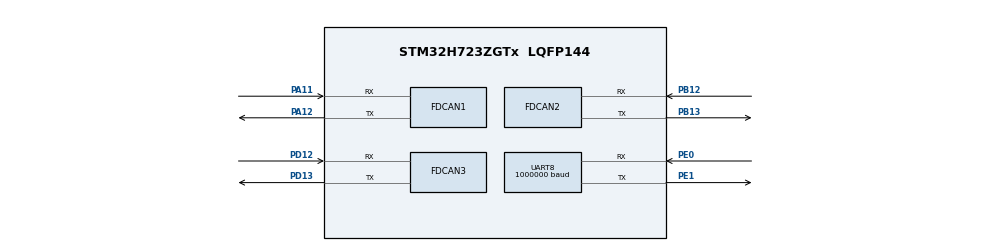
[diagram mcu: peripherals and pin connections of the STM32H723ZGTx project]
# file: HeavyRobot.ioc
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CORTEX_M7.default_mode_Activation=1
CRC.CRCLength=CRC_POLYLENGTH_16B
CRC.DefaultInitValueUse=DEFAULT_INIT_VALUE_DISABLE
CRC.DefaultPolynomialUse=DEFAULT_POLYNOMIAL_DISABLE
CRC.GeneratingPolynomial=X12+X5+X0
CRC.InitValue=0
CRC.InputDataInversionMode=CRC_INPUTDATA_INVERSION_BYTE
CRC.OutputDataInversionMode=CRC_OUTPUTDATA_INVERSION_ENABLE
Dma.Request0=UART8_RX
Dma.Request1=UART8_TX
Dma.UART8_RX.0.Direction=DMA_PERIPH_TO_MEMORY
Dma.UART8_RX.0.EventEnable=DISABLE
Dma.UART8_RX.0.FIFOMode=DMA_FIFOMODE_DISABLE
Dma.UART8_RX.0.Instance=DMA1_Stream0
Dma.UART8_RX.0.MemDataAlignment=DMA_MDATAALIGN_BYTE
Dma.UART8_RX.0.MemInc=DMA_MINC_ENABLE
Dma.UART8_RX.0.Mode=DMA_NORMAL
Dma.UART8_RX.0.PeriphDataAlignment=DMA_PDATAALIGN_BYTE
Dma.UART8_RX.0.PeriphInc=DMA_PINC_DISABLE
Dma.UART8_RX.0.Polarity=HAL_DMAMUX_REQ_GEN_RISING
Dma.UART8_RX.0.Priority=DMA_PRIORITY_LOW
Dma.UART8_RX.0.RequestNumber=1
Dma.UART8_RX.0.SignalID=NONE
Dma.UART8_RX.0.SyncEnable=DISABLE
Dma.UART8_RX.0.SyncPolarity=HAL_DMAMUX_SYNC_NO_EVENT
Dma.UART8_RX.0.SyncRequestNumber=1
Dma.UART8_RX.0.SyncSignalID=NONE
Dma.UART8_TX.1.Direction=DMA_MEMORY_TO_PERIPH
Dma.UART8_TX.1.EventEnable=DISABLE
Dma.UART8_TX.1.FIFOMode=DMA_FIFOMODE_DISABLE
Dma.UART8_TX.1.Instance=DMA1_Stream1
Dma.UART8_TX.1.MemDataAlignment=DMA_MDATAALIGN_BYTE
Dma.UART8_TX.1.MemInc=DMA_MINC_ENABLE
Dma.UART8_TX.1.Mode=DMA_NORMAL
Dma.UART8_TX.1.PeriphDataAlignment=DMA_PDATAALIGN_BYTE
Dma.UART8_TX.1.PeriphInc=DMA_PINC_DISABLE
Dma.UART8_TX.1.Polarity=HAL_DMAMUX_REQ_GEN_RISING
Dma.UART8_TX.1.Priority=DMA_PRIORITY_LOW
Dma.UART8_TX.1.RequestNumber=1
Dma.UART8_TX.1.SignalID=NONE
Dma.UART8_TX.1.SyncEnable=DISABLE
Dma.UART8_TX.1.SyncPolarity=HAL_DMAMUX_SYNC_NO_EVENT
Dma.UART8_TX.1.SyncRequestNumber=1
Dma.UART8_TX.1.SyncSignalID=NONE
FDCAN1.CalculateBaudRateNominal=960000
FDCAN1.CalculateTimeBitNominal=1041
FDCAN1.CalculateTimeQuantumNominal=104.16666666666666
FDCAN1.DataPrescaler=2
FDCAN1.DataSyncJumpWidth=15
FDCAN1.DataTimeSeg1=32
FDCAN1.DataTimeSeg2=15
FDCAN1.NominalPrescaler=10
FDCAN1.NominalSyncJumpWidth=15
FDCAN1.NominalTimeSeg1=7
FDCAN1.NominalTimeSeg2=2
FDCAN1.RxFifo0ElmtsNbr=4
FDCAN1.StdFiltersNbr=1
FDCAN1.TxFifoQueueElmtsNbr=3
FDCAN2.CalculateBaudRateNominal=1000000
FDCAN2.CalculateTimeBitNominal=1000
FDCAN2.CalculateTimeQuantumNominal=125.0
FDCAN2.DataPrescaler=2
FDCAN2.DataSyncJumpWidth=15
FDCAN2.DataTimeSeg1=32
FDCAN2.DataTimeSeg2=15
FDCAN2.FrameFormat=FDCAN_FRAME_CLASSIC
FDCAN2.MessageRAMOffset=512
FDCAN2.NominalPrescaler=12
FDCAN2.NominalSyncJumpWidth=15
FDCAN2.NominalTimeSeg1=5
FDCAN2.NominalTimeSeg2=2
FDCAN2.RxFifo0ElmtsNbr=4
FDCAN2.StdFiltersNbr=1
FDCAN2.TxFifoQueueElmtsNbr=8
FDCAN3.CalculateBaudRateNominal=960000
FDCAN3.CalculateTimeBitNominal=1041
FDCAN3.CalculateTimeQuantumNominal=104.16666666666666
FDCAN3.DataPrescaler=2
FDCAN3.DataSyncJumpWidth=15
FDCAN3.DataTimeSeg1=32
FDCAN3.DataTimeSeg2=15
FDCAN3.MessageRAMOffset=1024
FDCAN3.NominalPrescaler=10
FDCAN3.NominalSyncJumpWidth=15
FDCAN3.NominalTimeSeg1=7
FDCAN3.NominalTimeSeg2=2
FDCAN3.RxFifo0ElmtsNbr=4
FDCAN3.StdFiltersNbr=1
FDCAN3.TxFifoQueueElmtsNbr=3
FREERTOS.BinarySemaphores01=StartSem,Static,StartSemControlBlock,Depleted
FREERTOS.Tasks01=SafetyTask,48,512,StartSafetyTask,As weak,NULL,Static,SafetyTaskBuffer,SafetyTaskControlBlock;MotorTask,47,512,StartMotorTask,As weak,NULL,Static,MotorTaskBuffer,MotorTaskControlBlock;BodyTask,8,512,StartBodyTask,As weak,NULL,Static,RobotTaskBuffer,RobotTaskControlBlock
FREERTOS.configCHECK_FOR_STACK_OVERFLOW=2
FREERTOS.configTOTAL_HEAP_SIZE=50000
FREERTOS.configUSE_IDLE_HOOK=1
FREERTOS.configUSE_MALLOC_FAILED_HOOK=1
FREERTOS.configUSE_TICK_HOOK=1
Mcu.Family=STM32H7
Mcu.Name=STM32H723ZGTx
Mcu.Package=LQFP144
NVIC.DMA1_Stream0_IRQn=true\:5\:0\:false\:false\:true\:true\:true\:true\:true
NVIC.DMA1_Stream1_IRQn=true\:5\:0\:false\:false\:true\:true\:true\:true\:true
NVIC.FDCAN1_IT0_IRQn=true\:5\:0\:true\:false\:true\:true\:true\:true\:true
NVIC.FDCAN1_IT1_IRQn=true\:6\:0\:true\:false\:true\:true\:true\:true\:true
NVIC.FDCAN2_IT0_IRQn=true\:5\:0\:true\:false\:true\:true\:true\:true\:true
NVIC.FDCAN2_IT1_IRQn=true\:6\:0\:true\:false\:true\:true\:true\:true\:true
NVIC.FDCAN3_IT0_IRQn=true\:5\:0\:true\:false\:true\:true\:true\:true\:true
NVIC.FDCAN3_IT1_IRQn=true\:6\:0\:true\:false\:true\:true\:true\:true\:true
NVIC.PriorityGroup=NVIC_PRIORITYGROUP_4
NVIC.TIM17_IRQn=true\:15\:0\:false\:false\:true\:false\:false\:true\:true
NVIC.TIM1_UP_IRQn=true\:7\:0\:true\:false\:true\:true\:true\:true\:true
NVIC.TIM6_DAC_IRQn=true\:5\:0\:false\:false\:true\:true\:true\:true\:true
NVIC.TIM8_UP_TIM13_IRQn=true\:6\:0\:true\:false\:true\:true\:true\:true\:true
NVIC.TimeBase=TIM17_IRQn
NVIC.TimeBaseIP=TIM17
NVIC.UART8_IRQn=true\:5\:0\:false\:false\:true\:true\:true\:true\:true
PA11.Mode=FDCAN_Activate
PA11.Signal=FDCAN1_RX
PA12.Mode=FDCAN_Activate
PA12.Signal=FDCAN1_TX
PA13(JTMS/SWDIO).Mode=Serial_Wire
PA13(JTMS/SWDIO).Signal=DEBUG_JTMS-SWDIO
PA14(JTCK/SWCLK).Mode=Serial_Wire
PA14(JTCK/SWCLK).Signal=DEBUG_JTCK-SWCLK
PB12.Mode=FDCAN_Activate
PB12.Signal=FDCAN2_RX
PB13.Mode=FDCAN_Activate
PB13.Signal=FDCAN2_TX
PD12.Mode=FDCAN_Activate
PD12.Signal=FDCAN3_RX
PD13.Mode=FDCAN_Activate
PD13.Signal=FDCAN3_TX
PE0.Mode=Asynchronous
PE0.Signal=UART8_RX
PE1.Mode=Asynchronous
PE1.Signal=UART8_TX
PH0-OSC_IN.Mode=HSE-External-Oscillator
PH0-OSC_IN.Signal=RCC_OSC_IN
PH1-OSC_OUT.Mode=HSE-External-Oscillator
PH1-OSC_OUT.Signal=RCC_OSC_OUT
ProjectManager.HeapSize=0x400
ProjectManager.StackSize=0x200
ProjectManager.TargetToolchain=MDK-ARM V5.32
RCC.ADCFreq_Value=93750000
RCC.APB1Freq_Value=120000000
RCC.APB2Freq_Value=120000000
RCC.APB3Freq_Value=120000000
RCC.APB4Freq_Value=120000000
RCC.CortexFreq_Value=480000000
RCC.D1PPRE=RCC_APB3_DIV2
RCC.D2PPRE1=RCC_APB1_DIV2
RCC.D2PPRE2=RCC_APB2_DIV2
RCC.D3PPRE=RCC_APB4_DIV2
RCC.DIVM1=5
RCC.DIVM2=2
RCC.DIVN1=96
RCC.DIVN2=15
RCC.DIVN3=4
RCC.DIVP1=1
RCC.DIVQ1=5
RCC.HCLKFreq_Value=240000000
RCC.HPRE=RCC_HCLK_DIV2
RCC.HSE_VALUE=25000000
RCC.PLL2FRACN=0
RCC.PLL3FRACN=0
RCC.PLLFRACN=0
RCC.PLLSourceVirtual=RCC_PLLSOURCE_HSE
RCC.SYSCLKFreq_VALUE=480000000
RCC.SYSCLKSource=RCC_SYSCLKSOURCE_PLLCLK
RCC.SupplySource=PWR_LDO_SUPPLY
RCC.USBFreq_Value=96000000
TIM6.Period=1000-1
TIM6.Prescaler=240-1
UART8.BaudRate=1000000
VP_CRC_VS_CRC.Mode=CRC_Activate
VP_FREERTOS_VS_CMSIS_V2.Mode=CMSIS_V2
VP_MEMORYMAP_VS_MEMORYMAP.Mode=CurAppReg
VP_SYS_VS_tim17.Mode=TIM17
VP_TIM1_VS_ClockSourceINT.Mode=Internal
VP_TIM23_VS_ClockSourceINT.Mode=Internal
VP_TIM2_VS_ClockSourceINT.Mode=Internal
VP_TIM6_VS_ClockSourceINT.Mode=Enable_Timer
VP_TIM8_VS_ClockSourceINT.Mode=Internal
board=custom

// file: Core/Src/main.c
/* USER CODE BEGIN Header */
/**
  ******************************************************************************
  * @file           : main.c
  * @brief          : Main program body
  ******************************************************************************
  * @attention
  *
  * Copyright (c) 2026 STMicroelectronics.
  * All rights reserved.
  *
  * This software is licensed under terms that can be found in the LICENSE file
  * in the root directory of this software component.
  * If no LICENSE file comes with this software, it is provided AS-IS.
  *
  ******************************************************************************
  */
/* USER CODE END Header */
#include "main.h"
#include "FreeRTOS.h"
#include "cmsis_os2.h"
#include "crc.h"
#include "dma.h"
#include "fdcan.h"
#include "tim.h"
#include "usart.h"
#include "gpio.h"

/* USER CODE BEGIN Includes */
#include "arm_app.h"
#include <stdio.h>
/* USER CODE END Includes */

void SystemClock_Config(void);
static void MPU_Config(void);
void MX_FREERTOS_Init(void);

int main(void)
{

  /* MPU Configuration--------------------------------------------------------*/
  MPU_Config();

  /* MCU Configuration--------------------------------------------------------*/

  /* Reset of all peripherals, Initializes the Flash interface and the Systick. */
  HAL_Init();

  /* Configure the system clock */
  SystemClock_Config();

  /* Initialize all configured peripherals */
  MX_GPIO_Init();
  MX_DMA_Init();
  MX_FDCAN1_Init();
  MX_FDCAN2_Init();
  MX_FDCAN3_Init();
  MX_TIM1_Init();
  MX_TIM8_Init();
  MX_TIM2_Init();
  MX_CRC_Init();
  MX_TIM6_Init();
  MX_TIM23_Init();
  MX_UART8_Init();
  /* USER CODE BEGIN 2 */

///* 关节角 -> 位姿 */
//float q_seed[6] = {0.3f, -0.7f, 1.1f, 0.2f, 0.0f, -0.4f};
//ArmPos_t pose;
//Matrix4x4 T_target;
//Arm_ForwardKinematics(q_seed, &pose, &T_target);   /* T_out 不需要就传 NULL */

//ArmIK_Model ik;
//ArmIK_Init(&ik, arm_params);             /* arm_params 在 arm_kinematics.c */
//ArmIK_SetTool(&ik, 0.0f, 0.0f, 0.0f);

//ArmPos_t target = {
//    .x = 0.25f, .y = 0.0f, .z = 0.35f,
//    .roll = 0.0f, .pitch = 1.5708f, .yaw = 0.0f,
//};

////float q_seed[6] = {0.3f, -0.7f, 1.1f, 0.2f, 0.5f, -0.4f};
////float q_min[6]  = {NULL};//{ /* 或者传 NULL */ };
////float q_max[6]  = {NULL};//{ /* 或者传 NULL */ };
//float q_out[6];

//if (ArmIK_SolvePose(&ik, &pose, q_seed, NULL, NULL, q_out)) {
//    float err = ArmIK_Residual(T_target.data, q_out);
//}

  /* USER CODE END 2 */

  /* Init scheduler */
  osKernelInitialize();  /* Call init function for freertos objects (in cmsis_os2.c) */
  MX_FREERTOS_Init();

  /* Start scheduler */
  osKernelStart();

  /* We should never get here as control is now taken by the scheduler */

  /* Infinite loop */
  while (1)
  {

  }
}

void SystemClock_Config(void)
{
  RCC_OscInitTypeDef RCC_OscInitStruct = {0};
  RCC_ClkInitTypeDef RCC_ClkInitStruct = {0};

  /** Supply configuration update enable
  */
  HAL_PWREx_ConfigSupply(PWR_LDO_SUPPLY);

  /** Configure the main internal regulator output voltage
  */
  __HAL_PWR_VOLTAGESCALING_CONFIG(PWR_REGULATOR_VOLTAGE_SCALE0);

  while(!__HAL_PWR_GET_FLAG(PWR_FLAG_VOSRDY)) {}

  /** Initializes the RCC Oscillators according to the specified parameters
  * in the RCC_OscInitTypeDef structure.
  */
  RCC_OscInitStruct.OscillatorType = RCC_OSCILLATORTYPE_HSE;
  RCC_OscInitStruct.HSEState = RCC_HSE_ON;
  RCC_OscInitStruct.PLL.PLLState = RCC_PLL_ON;
  RCC_OscInitStruct.PLL.PLLSource = RCC_PLLSOURCE_HSE;
  RCC_OscInitStruct.PLL.PLLM = 5;
  RCC_OscInitStruct.PLL.PLLN = 96;
  RCC_OscInitStruct.PLL.PLLP = 1;
  RCC_OscInitStruct.PLL.PLLQ = 5;
  RCC_OscInitStruct.PLL.PLLR = 2;
  RCC_OscInitStruct.PLL.PLLRGE = RCC_PLL1VCIRANGE_2;
  RCC_OscInitStruct.PLL.PLLVCOSEL = RCC_PLL1VCOWIDE;
  RCC_OscInitStruct.PLL.PLLFRACN = 0;
  if (HAL_RCC_OscConfig(&RCC_OscInitStruct) != HAL_OK)
  {
    Error_Handler();
  }

  /** Initializes the CPU, AHB and APB buses clocks
  */
  RCC_ClkInitStruct.ClockType = RCC_CLOCKTYPE_HCLK|RCC_CLOCKTYPE_SYSCLK
                              |RCC_CLOCKTYPE_PCLK1|RCC_CLOCKTYPE_PCLK2
                              |RCC_CLOCKTYPE_D3PCLK1|RCC_CLOCKTYPE_D1PCLK1;
  RCC_ClkInitStruct.SYSCLKSource = RCC_SYSCLKSOURCE_PLLCLK;
  RCC_ClkInitStruct.SYSCLKDivider = RCC_SYSCLK_DIV1;
  RCC_ClkInitStruct.AHBCLKDivider = RCC_HCLK_DIV2;
  RCC_ClkInitStruct.APB3CLKDivider = RCC_APB3_DIV2;
  RCC_ClkInitStruct.APB1CLKDivider = RCC_APB1_DIV2;
  RCC_ClkInitStruct.APB2CLKDivider = RCC_APB2_DIV2;
  RCC_ClkInitStruct.APB4CLKDivider = RCC_APB4_DIV2;

  if (HAL_RCC_ClockConfig(&RCC_ClkInitStruct, FLASH_LATENCY_3) != HAL_OK)
  {
    Error_Handler();
  }
}

 /* MPU Configuration */

void MPU_Config(void)
{
  MPU_Region_InitTypeDef MPU_InitStruct = {0};

  /* Disables the MPU */
  HAL_MPU_Disable();

  /** Initializes and configures the Region and the memory to be protected
  */
  MPU_InitStruct.Enable = MPU_REGION_ENABLE;
  MPU_InitStruct.Number = MPU_REGION_NUMBER0;
  MPU_InitStruct.BaseAddress = 0x0;
  MPU_InitStruct.Size = MPU_REGION_SIZE_4GB;
  MPU_InitStruct.SubRegionDisable = 0x87;
  MPU_InitStruct.TypeExtField = MPU_TEX_LEVEL0;
  MPU_InitStruct.AccessPermission = MPU_REGION_NO_ACCESS;
  MPU_InitStruct.DisableExec = MPU_INSTRUCTION_ACCESS_DISABLE;
  MPU_InitStruct.IsShareable = MPU_ACCESS_SHAREABLE;
  MPU_InitStruct.IsCacheable = MPU_ACCESS_NOT_CACHEABLE;
  MPU_InitStruct.IsBufferable = MPU_ACCESS_NOT_BUFFERABLE;

  HAL_MPU_ConfigRegion(&MPU_InitStruct);
  /* Enables the MPU */
  HAL_MPU_Enable(MPU_PRIVILEGED_DEFAULT);

}

void HAL_TIM_PeriodElapsedCallback(TIM_HandleTypeDef *htim)
{
  if (htim->Instance == TIM17)
  {
    HAL_IncTick();
  }
}

void Error_Handler(void)
{
  __disable_irq();
  while (1)
  {
  }
}

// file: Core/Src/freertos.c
/* USER CODE BEGIN Header */
/**
  ******************************************************************************
  * File Name          : freertos.c
  * Description        : Code for freertos applications
  ******************************************************************************
  * @attention
  *
  * Copyright (c) 2026 STMicroelectronics.
  * All rights reserved.
  *
  * This software is licensed under terms that can be found in the LICENSE file
  * in the root directory of this software component.
  * If no LICENSE file comes with this software, it is provided AS-IS.
  *
  ******************************************************************************
  */
/* USER CODE END Header */

#include "FreeRTOS.h"
#include "task.h"
#include "main.h"
#include "FreeRTOS.h"
#include "cmsis_os2.h"

typedef StaticTask_t osStaticThreadDef_t;
typedef StaticSemaphore_t osStaticSemaphoreDef_t;

/* Definitions for SafetyTask */
osThreadId_t SafetyTaskHandle;
uint32_t SafetyTaskBuffer[ 512 ];
osStaticThreadDef_t SafetyTaskControlBlock;
const osThreadAttr_t SafetyTask_attributes = {
  .name = "SafetyTask",
  .cb_mem = &SafetyTaskControlBlock,
  .cb_size = sizeof(SafetyTaskControlBlock),
  .stack_mem = &SafetyTaskBuffer[0],
  .stack_size = sizeof(SafetyTaskBuffer),
  .priority = (osPriority_t) osPriorityRealtime,
};
/* Definitions for MotorTask */
osThreadId_t MotorTaskHandle;
uint32_t MotorTaskBuffer[ 512 ];
osStaticThreadDef_t MotorTaskControlBlock;
const osThreadAttr_t MotorTask_attributes = {
  .name = "MotorTask",
  .cb_mem = &MotorTaskControlBlock,
  .cb_size = sizeof(MotorTaskControlBlock),
  .stack_mem = &MotorTaskBuffer[0],
  .stack_size = sizeof(MotorTaskBuffer),
  .priority = (osPriority_t) osPriorityHigh7,
};
/* Definitions for BodyTask */
osThreadId_t BodyTaskHandle;
uint32_t RobotTaskBuffer[ 512 ];
osStaticThreadDef_t RobotTaskControlBlock;
const osThreadAttr_t BodyTask_attributes = {
  .name = "BodyTask",
  .cb_mem = &RobotTaskControlBlock,
  .cb_size = sizeof(RobotTaskControlBlock),
  .stack_mem = &RobotTaskBuffer[0],
  .stack_size = sizeof(RobotTaskBuffer),
  .priority = (osPriority_t) osPriorityLow,
};
/* Definitions for StartSem */
osSemaphoreId_t StartSemHandle;
osStaticSemaphoreDef_t StartSemControlBlock;
const osSemaphoreAttr_t StartSem_attributes = {
  .name = "StartSem",
  .cb_mem = &StartSemControlBlock,
  .cb_size = sizeof(StartSemControlBlock),
};

void StartSafetyTask(void *argument);
void StartMotorTask(void *argument);
void StartBodyTask(void *argument);

void MX_FREERTOS_Init(void); /* (MISRA C 2004 rule 8.1) */

/* Hook prototypes */
void vApplicationIdleHook(void);
void vApplicationTickHook(void);
void vApplicationStackOverflowHook(xTaskHandle xTask, char *pcTaskName);
void vApplicationMallocFailedHook(void);

/* USER CODE BEGIN 2 */
void vApplicationIdleHook( void )
{
   /* vApplicationIdleHook() will only be called if configUSE_IDLE_HOOK is set
   to 1 in FreeRTOSConfig.h. It will be called on each iteration of the idle
   task. It is essential that code added to this hook function never attempts
   to block in any way (for example, call xQueueReceive() with a block time
   specified, or call vTaskDelay()). If the application makes use of the
   vTaskDelete() API function (as this demo application does) then it is also
   important that vApplicationIdleHook() is permitted to return to its calling
   function, because it is the responsibility of the idle task to clean up
   memory allocated by the kernel to any task that has since been deleted. */
}
/* USER CODE END 2 */

/* USER CODE BEGIN 3 */
void vApplicationTickHook( void )
{
   /* This function will be called by each tick interrupt if
   configUSE_TICK_HOOK is set to 1 in FreeRTOSConfig.h. User code can be
   added here, but the tick hook is called from an interrupt context, so
   code must not attempt to block, and only the interrupt safe FreeRTOS API
   functions can be used (those that end in FromISR()). */
}
/* USER CODE END 3 */

/* USER CODE BEGIN 4 */
void vApplicationStackOverflowHook(xTaskHandle xTask,char *pcTaskName)
{
   /* Run time stack overflow checking is performed if
   configCHECK_FOR_STACK_OVERFLOW is defined to 1 or 2. This hook function is
   called if a stack overflow is detected. */
}
/* USER CODE END 4 */

/* USER CODE BEGIN 5 */
void vApplicationMallocFailedHook(void)
{
   /* vApplicationMallocFailedHook() will only be called if
   configUSE_MALLOC_FAILED_HOOK is set to 1 in FreeRTOSConfig.h. It is a hook
   function that will get called if a call to pvPortMalloc() fails.
   pvPortMalloc() is called internally by the kernel whenever a task, queue,
   timer or semaphore is created. It is also called by various parts of the
   demo application. If heap_1.c or heap_2.c are used, then the size of the
   heap available to pvPortMalloc() is defined by configTOTAL_HEAP_SIZE in
   FreeRTOSConfig.h, and the xPortGetFreeHeapSize() API function can be used
   to query the size of free heap space that remains (although it does not
   provide information on how the remaining heap might be fragmented). */
}
/* USER CODE END 5 */

void MX_FREERTOS_Init(void) {

  /* Create the semaphores(s) */
  /* creation of StartSem */
  StartSemHandle = osSemaphoreNew(1, 0, &StartSem_attributes);

  /* Create the thread(s) */
  /* creation of SafetyTask */
  SafetyTaskHandle = osThreadNew(StartSafetyTask, NULL, &SafetyTask_attributes);

  /* creation of MotorTask */
  MotorTaskHandle = osThreadNew(StartMotorTask, NULL, &MotorTask_attributes);

  /* creation of BodyTask */
  BodyTaskHandle = osThreadNew(StartBodyTask, NULL, &BodyTask_attributes);

}

__weak void StartSafetyTask(void *argument)
{
  for(;;)
  {
    osDelay(1);
  }
}

__weak void StartMotorTask(void *argument)
{
  for(;;)
  {
    osDelay(1);
  }
}

__weak void StartBodyTask(void *argument)
{
  for(;;)
  {
    osDelay(1);
  }
}
